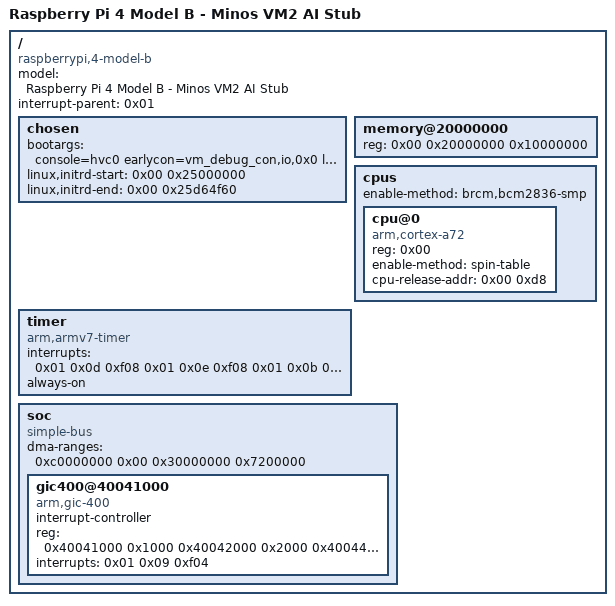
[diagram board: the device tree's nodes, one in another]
/dts-v1/;

/memreserve/	0x0000000020000000 0x0000000000001000;
/ {
	compatible = "raspberrypi,4-model-b\0brcm,bcm2711";
	model = "Raspberry Pi 4 Model B - Minos VM2 AI Stub";
	#address-cells = <0x02>;
	#size-cells = <0x01>;
	interrupt-parent = <0x01>;

	chosen {
		bootargs = "console=hvc0 earlycon=vm_debug_con,io,0x0 loglevel=7 no_console_suspend rdinit=/init";
		linux,initrd-start = <0x00 0x25000000>;
		linux,initrd-end = <0x00 0x25d64f60>;
	};

	memory@20000000 {
		device_type = "memory";
		reg = <0x00 0x20000000 0x10000000>;
	};

	cpus {
		#address-cells = <0x01>;
		#size-cells = <0x00>;
		enable-method = "brcm,bcm2836-smp";

		cpu@0 {
			device_type = "cpu";
			compatible = "arm,cortex-a72";
			reg = <0x00>;
			enable-method = "spin-table";
			cpu-release-addr = <0x00 0xd8>;
		};
	};

	timer {
		compatible = "arm,armv7-timer";
		interrupts = <0x01 0x0d 0xf08 0x01 0x0e 0xf08 0x01 0x0b 0xf08 0x01 0x0a 0xf08>;
		always-on;
	};

	soc {
		compatible = "simple-bus";
		#address-cells = <0x01>;
		#size-cells = <0x01>;
		ranges = <0x7e000000 0x00 0xfe000000 0x1800000 0x7c000000 0x00 0xfc000000 0x2000000 0x40000000 0x00 0xff800000 0x800000>;
		dma-ranges = <0xc0000000 0x00 0x30000000 0x7200000>;

		gic400@40041000 {
			compatible = "arm,gic-400";
			interrupt-controller;
			#interrupt-cells = <0x03>;
			reg = <0x40041000 0x1000 0x40042000 0x2000 0x40044000 0x2000 0x40046000 0x2000>;
			interrupts = <0x01 0x09 0xf04>;
			phandle = <0x01>;
		};
	};
};
